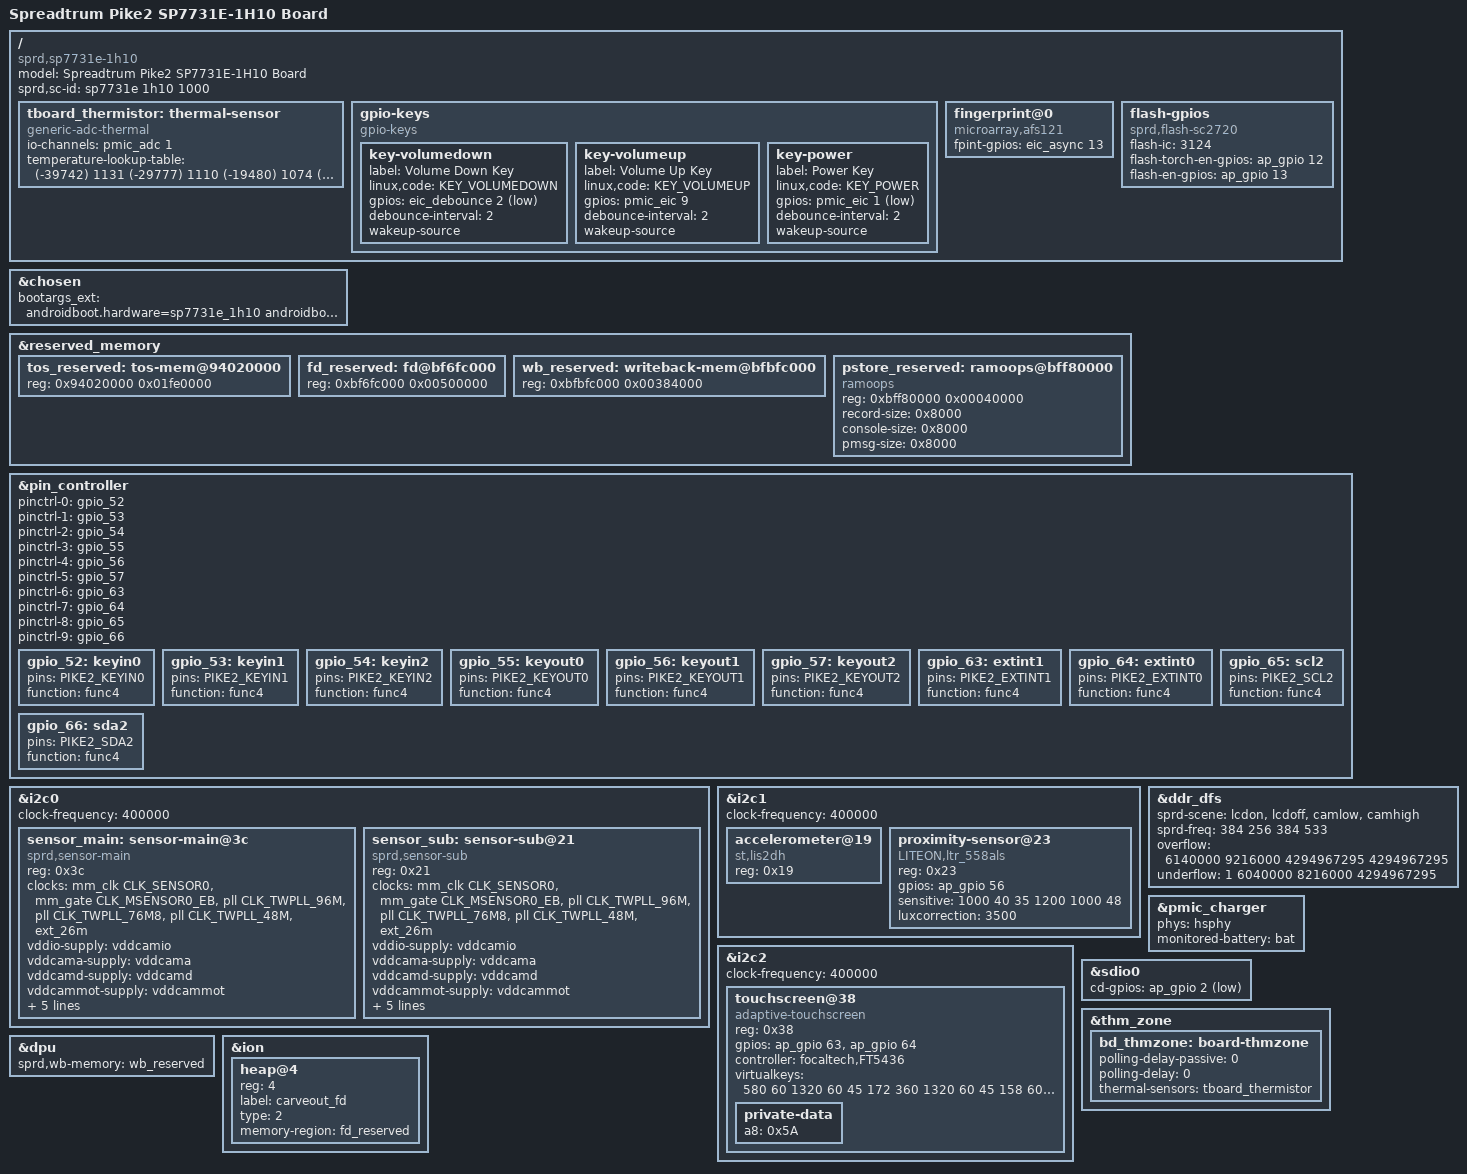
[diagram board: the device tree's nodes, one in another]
/*
 * Spreadtrum sharkle sp7731e board DTS file
 *
 * Copyright (C) 2019, Spreadtrum Communications Inc.
 *
 * This file is licensed under a dual GPLv2 or X11 license.
 */
/dts-v1/;
/plugin/;
#include <dt-bindings/input/input.h>
#include <dt-bindings/gpio/gpio.h>
#include <dt-bindings/clock/sprd,sc7731e-clk.h>

/ {
	model = "Spreadtrum Pike2 SP7731E-1H10 Board";

	compatible = "sprd,sp7731e-1h10", "sprd,sc7731e";

	sprd,sc-id = "sp7731e 1h10 1000";

	/*
	* When create a new node, we should use the key word __overlay__,
	* otherwise u-boot can not analyze it.
	*/
	fragment {
		target-path = "/";
		__overlay__ {

			tboard_thermistor:thermal-sensor {
				compatible = "generic-adc-thermal";
				#thermal-sensor-cells = <0>;
				io-channels = <&pmic_adc 1>;
				io-channel-names = "sensor-channel";
				temperature-lookup-table = <    (-39742) 1131
								(-29777) 1110
								(-19480) 1074
								(-4679) 983
								10110 838
								24805 654
								44922 413
								54903 316
								64895 238
								74884 178
								84883 133
								94883 100
								104880 75
								114889 57
								124872 43 >;
			};

			gpio-keys {
				compatible = "gpio-keys";

				key-volumedown {
					label = "Volume Down Key";
					linux,code = <KEY_VOLUMEDOWN>;
					gpios = <&eic_debounce 2 GPIO_ACTIVE_LOW>;
					debounce-interval = <2>;
					wakeup-source;
				};

				key-volumeup {
					label = "Volume Up Key";
					linux,code = <KEY_VOLUMEUP>;
					gpios = <&pmic_eic 9 GPIO_ACTIVE_HIGH>;
					debounce-interval = <2>;
					wakeup-source;
				};

				key-power {
					label = "Power Key";
					linux,code = <KEY_POWER>;
					gpios = <&pmic_eic 1 GPIO_ACTIVE_LOW>;
					debounce-interval = <2>;
					wakeup-source;
				};
			};

			fingerprint@0 {
				compatible = "microarray,afs121";
				fpint-gpios = <&eic_async 13 0>;
			};

			flash-gpios {
				compatible = "sprd,flash-sc2720";
				flash-ic = <3124>;
				flash-torch-en-gpios = <&ap_gpio 12 0>;
				flash-en-gpios = <&ap_gpio 13 0>;
			};

		};
	};
};

&chosen {
	bootargs_ext = "androidboot.hardware=sp7731e_1h10 androidboot.dtbo_idx=0";
};

&reserved_memory {
	tos_reserved: tos-mem@94020000 {
		reg = <0x94020000 0x01fe0000>;
	};

	fd_reserved: fd@bf6fc000 {
		reg = <0xbf6fc000 0x00500000>;
	};

	wb_reserved: writeback-mem@bfbfc000 {
		reg = <0xbfbfc000 0x00384000>;
	};

	pstore_reserved: ramoops@bff80000 {
		compatible = "ramoops";
		reg = <0xbff80000 0x00040000>;
		record-size = <0x8000>;
		console-size = <0x8000>;
		pmsg-size = <0x8000>;
	};
};

&pin_controller {
	pinctrl-names =
	/* keyin0 ~ keyin2 */
	"gpio_52", "gpio_53", "gpio_54",
	/* keyout0 ~ keyout2 */
	"gpio_55", "gpio_56", "gpio_57",
	/* extint1, extint0, scl2, sda2 */
	"gpio_63", "gpio_64", "gpio_65", "gpio_66";
	pinctrl-0 = <&gpio_52>;
	pinctrl-1 = <&gpio_53>;
	pinctrl-2 = <&gpio_54>;
	pinctrl-3 = <&gpio_55>;
	pinctrl-4 = <&gpio_56>;
	pinctrl-5 = <&gpio_57>;
	pinctrl-6 = <&gpio_63>;
	pinctrl-7 = <&gpio_64>;
	pinctrl-8 = <&gpio_65>;
	pinctrl-9 = <&gpio_66>;

	gpio_52: keyin0 {
		pins = "PIKE2_KEYIN0";
		function = "func4";
	};

	gpio_53: keyin1 {
		pins = "PIKE2_KEYIN1";
		function = "func4";
	};

	gpio_54: keyin2 {
		pins = "PIKE2_KEYIN2";
		function = "func4";
	};

	gpio_55: keyout0 {
		pins = "PIKE2_KEYOUT0";
		function = "func4";
	};

	gpio_56: keyout1 {
		pins = "PIKE2_KEYOUT1";
		function = "func4";
	};

	gpio_57: keyout2 {
		pins = "PIKE2_KEYOUT2";
		function = "func4";
	};

	gpio_63: extint1 {
		pins = "PIKE2_EXTINT1";
		function = "func4";
	};

	gpio_64: extint0 {
		pins = "PIKE2_EXTINT0";
		function = "func4";
	};

	gpio_65: scl2 {
		pins = "PIKE2_SCL2";
		function = "func4";
	};

	gpio_66: sda2 {
		pins = "PIKE2_SDA2";
		function = "func4";
	};
};

&i2c0 {
	status = "okay";
	clock-frequency = <400000>;
	sensor_main: sensor-main@3c {
		compatible = "sprd,sensor-main";
		reg = <0x3c>;
		clock-names = "clk_src", "sensor_eb",
			"clk_96m", "clk_76m8",
			"clk_48m", "clk_26m";
		clocks  = <&mm_clk CLK_SENSOR0>,
			<&mm_gate CLK_MSENSOR0_EB>,
			<&pll CLK_TWPLL_96M>,
			<&pll CLK_TWPLL_76M8>,
			<&pll CLK_TWPLL_48M>,
			<&ext_26m>;
		vddio-supply = <&vddcamio>;
		vddcama-supply = <&vddcama>;
		vddcamd-supply = <&vddcamd>;
		vddcammot-supply = <&vddcammot>;
		reset-gpios = <&ap_gpio 37 0>;
		power-down-gpios = <&ap_gpio 38 0>;
		host = "dcam0";
		sprd,phyid = <0>;
		csi = <&csi0>;
	};

	sensor_sub: sensor-sub@21 {
		compatible = "sprd,sensor-sub";
		reg = <0x21>;
		clock-names = "clk_src","sensor_eb",
			"clk_96m", "clk_76m8",
			"clk_48m", "clk_26m";
		clocks = <&mm_clk CLK_SENSOR0>,
			<&mm_gate CLK_MSENSOR0_EB>,
			<&pll CLK_TWPLL_96M>,
			<&pll CLK_TWPLL_76M8>,
			<&pll CLK_TWPLL_48M>,
			<&ext_26m>;
		vddio-supply = <&vddcamio>;
		vddcama-supply = <&vddcama>;
		vddcamd-supply = <&vddcamd>;
		vddcammot-supply = <&vddcammot>;
		reset-gpios = <&ap_gpio 46 0>;
		power-down-gpios = <&ap_gpio 39 0>;
		host = "dcam0";
		sprd,phyid = <0>;
		csi = <&csi0>;
	};
};

&i2c1 {
	status = "okay";
	clock-frequency = <400000>;

	accelerometer@19 {
		compatible = "st,lis2dh", "st,lis2dh12";
		reg = <0x19>;
	};

	proximity-sensor@23 {
		compatible = "LITEON,ltr_558als";
		reg = <0x23>;
		gpios = <&ap_gpio 56 GPIO_ACTIVE_HIGH>;
		/*
		 *low sensitve(def):1500,250,220,1800,1600,1;
		 *have no sensitve=<> as def.
		 * High sensitve:1000,40,35,1200,1000,48
		 */
		sensitive = <1000 40 35
					1200 1000 48>;
		luxcorrection = <3500>;
	};
};

&i2c2 {
	status = "okay";
	clock-frequency = <400000>;
	touchscreen@38 {
		compatible = "adaptive-touchscreen";
		reg = <0x38>;
		gpios = <&ap_gpio 63 GPIO_ACTIVE_HIGH
			&ap_gpio 64 GPIO_ACTIVE_HIGH>;
		controller = "focaltech,FT5436";
		virtualkeys = <580 60 1320 60 45
			172 360 1320 60 45
			158 600 1320 60 45>;
		private-data {
			a8 = /bits/ 8 <0x5A>;
		};
	};
};

&ddr_dfs {
	sprd-scene = "lcdon", "lcdoff", "camlow", "camhigh";
	sprd-freq = <384 256 384 533>;
	overflow = <6140000 9216000 4294967295 4294967295>;
	underflow = <1 6040000 8216000 4294967295>;
};

&pmic_charger {
	status = "okay";
	phys = <&hsphy>;
	monitored-battery = <&bat>;
};

&sdio0 {
	cd-gpios = <&ap_gpio 2 1>;
};

&thm_zone {
	bd_thmzone: board-thmzone {
		polling-delay-passive = <0>;
		polling-delay = <0>;
		thermal-sensors = <&tboard_thermistor>;
	};
};

&dpu {
	status = "okay";
	sprd,wb-memory = <&wb_reserved>;
};

&ion {
	heap@4 {
		reg = <4>;
		label = "carveout_fd";
		type = <2>;
		memory-region = <&fd_reserved>;
	};
};
